# L3INIT_PRM register map
Vendor: Texas Instruments
Peripheral module from a debugger description file (folder TDA2Px).
Registers are 32-bit, access per field, reset 0x0 unless marked. A register's access mark holds for its fields unless they carry their own. Offsets are as the file gives them; lines under a group give offsets from that group; [hi:lo] are bit positions; {n}, {i} and the like mark numbered series; 'fields as' and 'values as' point back to an identical list; <NAME> marks a mode.

## L3INIT_PRM
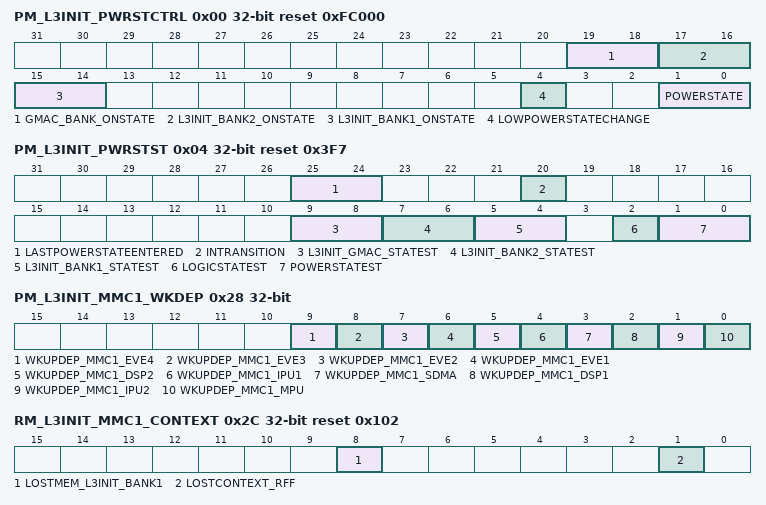
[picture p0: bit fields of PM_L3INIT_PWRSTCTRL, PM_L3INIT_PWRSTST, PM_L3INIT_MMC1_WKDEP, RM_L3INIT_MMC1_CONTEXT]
0x00 PM_L3INIT_PWRSTCTRL reset 0xFC000 — This register controls the L3INIT power state to reach upon a domain sleep transition Note: In the L3INIT power domain OFF state is only allowed in systems where Ethernet RGMII is NOT used in the system - this is very application specific and may not be available in all TI standard software offerings.
  [19:18] GMAC_BANK_ONSTATE ro — GMAC BANK state when domain is ON.
    3=MEM_ON (Memory bank is on when the domain is ON.)
  [17:16] L3INIT_BANK2_ONSTATE ro — L3INIT BANK2 state when domain is ON.
    3=MEM_ON (Memory bank is on when the domain is ON.)
  [15:14] L3INIT_BANK1_ONSTATE ro — L3INIT BANK1 state when domain is ON.
    3=MEM_ON (Memory bank is on when the domain is ON.)
  [4] LOWPOWERSTATECHANGE rw — Power state change request when domain has already performed a sleep transition. Allows going into deeper low power state without waking up the power domain.
    0=DIS (Do not request a low power state change.); 1=EN (Request a low power state change. This bit is automatically cleared when the power state is effectively changed or when power state is ON.)
  [1:0] POWERSTATE rw — Power state control
    0=OFF (OFF state); 1=RET (Reserved); 2=INACT (Reserved); 3=ON (ON State)
0x04 PM_L3INIT_PWRSTST reset 0x3F7 — This register provides a status on the current L3INIT power domain state. [warm reset insensitive]
  [25:24] LASTPOWERSTATEENTERED rw — Last low power state entered. Set to 0x3 upon write of the same only. This register is intended for debug purpose only.
    0=OFF (Power domain was previously OFF); 1=RET (Reserved); 2=INACTIVE (Reserved); 3=ON (Power domain was previously ON-ACTIVE)
  [20] INTRANSITION ro — Domain transition status
    0=NO (No on-going transition on power domain); 1=ONGOING (Power domain transition is in progress.)
  [9:8] L3INIT_GMAC_STATEST ro — L3INIT GMAC state status
    0=MEM_OFF (Memory is OFF); 3=MEM_ON (Memory is ON)
  [7:6] L3INIT_BANK2_STATEST ro — L3INIT BANK2 state status
    0=MEM_OFF (Memory is OFF); 1=MEM_RET (Reserved); 3=MEM_ON (Memory is ON)
  [5:4] L3INIT_BANK1_STATEST ro — L3INIT BANK1 state status
    0=MEM_OFF (Memory is OFF); 3=MEM_ON (Memory is ON)
  [2] LOGICSTATEST ro — Logic state status
    0=OFF (Reserved); 1=ON (Logic in domain is ON)
  [1:0] POWERSTATEST ro — Current power state status
    0=OFF (Power domain is OFF); 1=RET (Reserved); 2=INACTIVE (Reserved); 3=ON (Power domain is ON-ACTIVE)
0x10 RM_PCIESS_RSTCTRL reset 0x1 — This register controls the release of the PCIESS local reset.
  [0] RST_LOCAL_PCIE1 rw — PCIESS1 local reset control
    0=CLEAR (Reset is cleared for the IVA Sequencer CPU1); 1=ASSERT (Reset is asserted for the IVA sequencer CPU1)
0x14 RM_PCIESS_RSTST — This register logs the different reset sources of the PCIESS domain. Each bit is set upon release of the domain reset signal. Must be cleared by software. [warm reset insensitive]
  [0] RST_LOCAL_PCIE1 rw — PCIESS1 local SW reset
    0=RESET_NO (No SW reset occurred); 1=RESET_YES (Sequencer1 has been reset upon SW reset)
0x28 PM_L3INIT_MMC1_WKDEP — This register controls wakeup dependency based on MMC1 service requests.
  [all] fields
    0=DISABLED (Dependency is disabled); 1=ENABLED (Dependency is enabled)
  [9] WKUPDEP_MMC1_EVE4 rw — Wakeup dependency from MMC1 module (SWakeup signal) towards EVE4 + L3_MAIN1 + L4PER1 + L4PER2 + L4PER3 domainsEVE4 is not supported in this family of devices.
  [8] WKUPDEP_MMC1_EVE3 rw — Wakeup dependency from MMC1 module (SWakeup signal) towards EVE3 + L3_MAIN1 + L4PER1 + L4PER2 + L4PER3 domainsEVE3 is not supported in this family of devices.
  [7] WKUPDEP_MMC1_EVE2 rw — Wakeup dependency from MMC1 module (SWakeup signal) towards EVE2 + L3_MAIN1 + L4PER1 + L4PER2 + L4PER3 domains
  [6] WKUPDEP_MMC1_EVE1 rw — Wakeup dependency from MMC1 module (SWakeup signal) towards EVE1 + L3_MAIN1 + L4PER1 + L4PER2 + L4PER3 domains
  [5] WKUPDEP_MMC1_DSP2 rw — Wakeup dependency from MMC1 module (SWakeup signal) towards DSP2 + L3_MAIN1 + L4PER1 + L4PER2 + L4PER3 domains
  [4] WKUPDEP_MMC1_IPU1 rw — Wakeup dependency from MMC1 module (SWakeup signal) towards IPU1 + L3_MAIN1 + L4PER1 + L4PER2 + L4PER3 domains
  [3] WKUPDEP_MMC1_SDMA rw — Wakeup dependency from MMC1 module (SWakeup signal) towards SDMA + L3MAIN1 + L4PER1 + L4PER2 + L4PER3 domains
  [2] WKUPDEP_MMC1_DSP1 rw — Wakeup dependency from MMC1 module (SWakeup signal) towards DSP1 + L3_MAIN1 + L4PER1 + L4PER2 + L4PER3 domains
  [1] WKUPDEP_MMC1_IPU2 rw — Wakeup dependency from MMC1 module (SWakeup signal) towards IPU2 + L3_MAIN1 + L4PER1 + L4PER2 + L4PER3 domains
  [0] WKUPDEP_MMC1_MPU rw — Wakeup dependency from MMC1 module (SWakeup signal) towards MPU + L3_MAIN1 + L4PER1 + L4PER2 + L4PER3 domains
0x2C RM_L3INIT_MMC1_CONTEXT reset 0x102 — This register contains dedicated MMC1 context statuses. [warm reset insensitive]
  [8] LOSTMEM_L3INIT_BANK1 rw — Specify if memory-based context in L3INIT_BANK1 memory bank has been lost due to a previous power transition or other reset source.
    0=MAINTAINED (Context has been maintained); 1=LOST (Context has been lost)
  [1] LOSTCONTEXT_RFF rw — Specify if RFF-based context has been lost due to a previous power transition or other reset source. (set upon assertion of L3INIT_RET_RST signal)
    values as LOSTMEM_L3INIT_BANK1
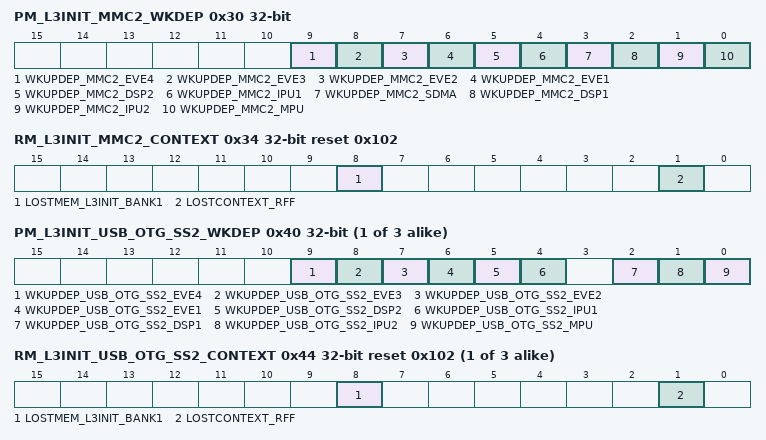
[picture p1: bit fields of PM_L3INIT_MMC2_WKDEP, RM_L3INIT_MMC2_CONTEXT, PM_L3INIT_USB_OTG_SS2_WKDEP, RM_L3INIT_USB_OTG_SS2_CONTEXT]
0x30 PM_L3INIT_MMC2_WKDEP — This register controls wakeup dependency based on MMC2 service requests.
  [all] fields
    values as the fields of PM_L3INIT_MMC1_WKDEP
  [9] WKUPDEP_MMC2_EVE4 rw — Wakeup dependency from MMC2 module (SWakeup signal) towards EVE4 + L3_MAIN1 + L4PER1 + L4PER2 + L4PER3 domainsEVE4 is not supported in this family of devices.
  [8] WKUPDEP_MMC2_EVE3 rw — Wakeup dependency from MMC2 module (SWakeup signal) towards EVE3 + L3_MAIN1 + L4PER1 + L4PER2 + L4PER3 domainsEVE3 is not supported in this family of devices.
  [7] WKUPDEP_MMC2_EVE2 rw — Wakeup dependency from MMC2 module (SWakeup signal) towards EVE2 + L3_MAIN1 + L4PER1 + L4PER2 + L4PER3 domains
  [6] WKUPDEP_MMC2_EVE1 rw — Wakeup dependency from MMC2 module (SWakeup signal) towards EVE1 + L3_MAIN1 + L4PER1 + L4PER2 + L4PER3 domains
  [5] WKUPDEP_MMC2_DSP2 rw — Wakeup dependency from MMC2 module (SWakeup signal) towards DSP2 + L3_MAIN1 + L4PER1 + L4PER2 + L4PER3 domains
  [4] WKUPDEP_MMC2_IPU1 rw — Wakeup dependency from MMC2 module (SWakeup signal) towards IPU1 + L3_MAIN1 + L4PER1 + L4PER2 + L4PER3 domains
  [3] WKUPDEP_MMC2_SDMA rw — Wakeup dependency from MMC2 module (SWakeup signal) towards SDMA + L3MAIN1 + L4PER1 + L4PER2 + L4PER3 domains
  [2] WKUPDEP_MMC2_DSP1 rw — Wakeup dependency from MMC2 module (SWakeup signal) towards DSP1 + L3_MAIN1 + L4PER1 + L4PER2 + L4PER3 domains
  [1] WKUPDEP_MMC2_IPU2 rw — Wakeup dependency from MMC2 module (SWakeup signal) towards IPU2 + L3_MAIN1 + L4PER1 + L4PER2 + L4PER3 domains
  [0] WKUPDEP_MMC2_MPU rw — Wakeup dependency from MMC2 module (SWakeup signal) towards MPU + L3_MAIN1 + L4PER1 + L4PER2 + L4PER3 domains
0x34 RM_L3INIT_MMC2_CONTEXT reset 0x102 — This register contains dedicated MMC2 context statuses. [warm reset insensitive]
  fields as RM_L3INIT_MMC1_CONTEXT
{0x30+8i} PM_L3INIT_USB_OTG_SS{i}_WKDEP (i=2..4) — This register controls wakeup dependency based on USB_OTG_SS{i} service requests.
  [all] fields
    values as the fields of PM_L3INIT_MMC1_WKDEP
  [9] WKUPDEP_USB_OTG_SS{i}_EVE4 rw — Wakeup dependency from USB{i} module (SWakeup signal) towards EVE4 + L3_MAIN1 + L4PER1 + L4PER2 + L4PER3 domainsEVE4 is not supported in this family of devices.
  [8] WKUPDEP_USB_OTG_SS{i}_EVE3 rw — Wakeup dependency from USB{i} module (SWakeup signal) towards EVE3 + L3_MAIN1 + L4PER1 + L4PER2 + L4PER3 domainsEVE3 is not supported in this family of devices.
  [7] WKUPDEP_USB_OTG_SS{i}_EVE2 rw — Wakeup dependency from USB{i} module (SWakeup signal) towards EVE2 + L3_MAIN1 + L4PER1 + L4PER2 + L4PER3 domains
  [6] WKUPDEP_USB_OTG_SS{i}_EVE1 rw — Wakeup dependency from USB{i} module (SWakeup signal) towards EVE1 + L3_MAIN1 + L4PER1 + L4PER2 + L4PER3 domains
  [5] WKUPDEP_USB_OTG_SS{i}_DSP2 rw — Wakeup dependency from USB{i} module (SWakeup signal) towards DSP2 + L3_MAIN1 + L4PER1 + L4PER2 + L4PER3 domains
  [4] WKUPDEP_USB_OTG_SS{i}_IPU1 rw — Wakeup dependency from USB{i} module (SWakeup signal) towards IPU1 + L3_MAIN1 + L4PER1 + L4PER2 + L4PER3 domains
  [2] WKUPDEP_USB_OTG_SS{i}_DSP1 rw — Wakeup dependency from USB{i} module (SWakeup signal) towards DSP1 + L3_MAIN1 + L4PER1 + L4PER2 + L4PER3 domains
  [1] WKUPDEP_USB_OTG_SS{i}_IPU2 rw — Wakeup dependency from USB{i} module (SWakeup signal) towards IPU2 + L3_MAIN1 + L4PER1 + L4PER2 + L4PER3 domains
  [0] WKUPDEP_USB_OTG_SS{i}_MPU rw — Wakeup dependency from USB{i} module (SWakeup signal) towards MPU + L3_MAIN1 + L4PER1 + L4PER2 + L4PER3 domains
{0x34+8i} RM_L3INIT_USB_OTG_SS{i}_CONTEXT reset 0x102 (i=2..4) — This register contains dedicated USB_OTG_SS{i} context statuses. [warm reset insensitive]
  fields as RM_L3INIT_MMC1_CONTEXT
0x7C RM_L3INIT_IEEE1500_2_OCP_CONTEXT reset 0x1 — This register contains dedicated IEEE1500_2_OCP context statuses. [warm reset insensitive]
  [0] LOSTCONTEXT_DFF rw — Specify if DFF-based context has been lost due to a previous power transition or other reset source. (set upon assertion of L3INIT_RST signal)
    values as RM_L3INIT_MMC1_CONTEXT.LOSTMEM_L3INIT_BANK1
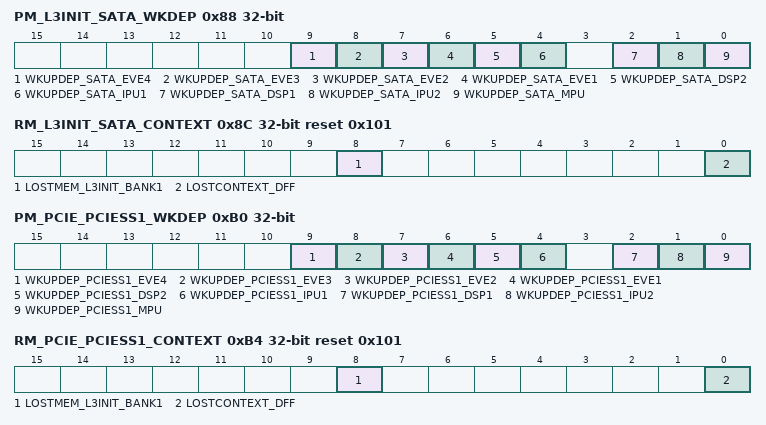
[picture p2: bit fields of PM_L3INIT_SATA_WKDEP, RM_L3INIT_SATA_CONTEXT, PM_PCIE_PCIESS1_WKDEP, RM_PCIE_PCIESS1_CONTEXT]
0x88 PM_L3INIT_SATA_WKDEP — This register controls wakeup dependency based on SATA service requests.
  [all] fields
    values as the fields of PM_L3INIT_MMC1_WKDEP
  [9] WKUPDEP_SATA_EVE4 rw — Wakeup dependency from SATA module (SWakeup signal) towards EVE4 + L3_MAIN1 + L4PER1 + L4PER2 + L4PER3 domainsEVE4 is not supported in this family of devices.
  [8] WKUPDEP_SATA_EVE3 rw — Wakeup dependency from SATA module (SWakeup signal) towards EVE3 + L3_MAIN1 + L4PER1 + L4PER2 + L4PER3 domainsEVE3 is not supported in this family of devices.
  [7] WKUPDEP_SATA_EVE2 rw — Wakeup dependency from SATA module (SWakeup signal) towards EVE2 + L3_MAIN1 + L4PER1 + L4PER2 + L4PER3 domains
  [6] WKUPDEP_SATA_EVE1 rw — Wakeup dependency from SATA module (SWakeup signal) towards EVE1 + L3_MAIN1 + L4PER1 + L4PER2 + L4PER3 domains
  [5] WKUPDEP_SATA_DSP2 rw — Wakeup dependency from SATA module (SWakeup signal) towards DSP2 + L3_MAIN1 + L4PER1 + L4PER2 + L4PER3 domains
  [4] WKUPDEP_SATA_IPU1 rw — Wakeup dependency from SATA module (SWakeup signal) towards IPU1 + L3_MAIN1 + L4PER1 + L4PER2 + L4PER3 domains
  [2] WKUPDEP_SATA_DSP1 rw — Wakeup dependency from SATA module (SWakeup signal) towards DSP1 + L3_MAIN1 + L4PER1 + L4PER2 + L4PER3 domains
  [1] WKUPDEP_SATA_IPU2 rw — Wakeup dependency from SATA module (SWakeup signal) towards IPU2 + L3_MAIN1 + L4PER1 + L4PER2 + L4PER3 domains
  [0] WKUPDEP_SATA_MPU rw — Wakeup dependency from SATA module (SWakeup signal) towards MPU + L3MAIN1 + L4CFG domains
0x8C RM_L3INIT_SATA_CONTEXT reset 0x101 — This register contains dedicated SATA context statuses. [warm reset insensitive]
  [8] LOSTMEM_L3INIT_BANK1 rw — Specify if memory-based context in L3INIT_BANK1 memory bank has been lost due to a previous power transition or other reset source.
    values as RM_L3INIT_MMC1_CONTEXT.LOSTMEM_L3INIT_BANK1
  [0] LOSTCONTEXT_DFF rw — Specify if DFF-based context has been lost due to a previous power transition or other reset source. (set upon assertion of L3INIT_RST signal)
    values as RM_L3INIT_MMC1_CONTEXT.LOSTMEM_L3INIT_BANK1
0xB0 PM_PCIE_PCIESS1_WKDEP — This register controls wakeup dependency based on PCIESS1 service requests.
  [9] WKUPDEP_PCIESS1_EVE4 rw — Wakeup dependency from PCIESS1 module (SWakeup signal) towards EVE4 + L3_MAIN1 + L4PER1 + L4PER2 + L4PER3 domainsEVE4 is not supported in this family of devices.
    values as the fields of PM_L3INIT_MMC1_WKDEP
  [8] WKUPDEP_PCIESS1_EVE3 rw — Wakeup dependency from PCIESS1 module (SWakeup signal) towards EVE3 + L3_MAIN1 + L4PER1 + L4PER2 + L4PER3 domainsEVE3 is not supported in this family of devices.
    values as the fields of PM_L3INIT_MMC1_WKDEP
  [7] WKUPDEP_PCIESS1_EVE2 rw — Wakeup dependency from PCIESS1 module (SWakeup signal) towards EVE2 + L3_MAIN1 + L4PER1 + L4PER2 + L4PER3 domains
    values as the fields of PM_L3INIT_MMC1_WKDEP
  [6] WKUPDEP_PCIESS1_EVE1 rw — Wakeup dependency from PCIESS1 module (SWakeup signal) towards EVE1 + L3_MAIN1 + L4PER1 + L4PER2 + L4PER3 domains
    values as the fields of PM_L3INIT_MMC1_WKDEP
  [5] WKUPDEP_PCIESS1_DSP2 rw — Wakeup dependency from PCIESS1 module (SWakeup signal) towards DSP2 + L3_MAIN1 + L4PER1 + L4PER2 + L4PER3 domains
    values as the fields of PM_L3INIT_MMC1_WKDEP
  [4] WKUPDEP_PCIESS1_IPU1 rw — Wakeup dependency from PCIESS1 module (SWakeup signal) towards IPU1 + L3_MAIN1 + L4PER1 + L4PER2 + L4PER3 domains
    values as the fields of PM_L3INIT_MMC1_WKDEP
  [2] WKUPDEP_PCIESS1_DSP1 rw — Wakeup dependency from PCIESS1 module (SWakeup signal) towards DSP1 + L3_MAIN1 + L4PER1 + L4PER2 + L4PER3 domains
    values as the fields of PM_L3INIT_MMC1_WKDEP
  [1] WKUPDEP_PCIESS1_IPU2 rw — Wakeup dependency from PCIESS1 module (SWakeup signal) towards IPU2 + L3_MAIN1 + L4PER1 + L4PER2 + L4PER3 domains
    0=Dependency_is_disabled; 1=Dependency_is_enabled
  [0] WKUPDEP_PCIESS1_MPU rw — Wakeup dependency from PCIESS1 module (SWakeup signal) towards MPU + L3_MAIN1 + L4PER1 + L4PER2 + L4PER3 domains
    values as the fields of PM_L3INIT_MMC1_WKDEP
0xB4 RM_PCIE_PCIESS1_CONTEXT reset 0x101 — This register contains dedicated PCIESS1 context statuses. [warm reset insensitive]
  [8] LOSTMEM_L3INIT_BANK1 rw — Specify if memory-based context in PCIESS1_BANK memory bank has been lost due to a previous power transition or other reset source.
    values as RM_L3INIT_MMC1_CONTEXT.LOSTMEM_L3INIT_BANK1
  [0] LOSTCONTEXT_DFF rw — Specify if DFF-based context has been lost due to a previous power transition or other reset source. (set upon assertion of L3INIT_RST signal)
    values as RM_L3INIT_MMC1_CONTEXT.LOSTMEM_L3INIT_BANK1
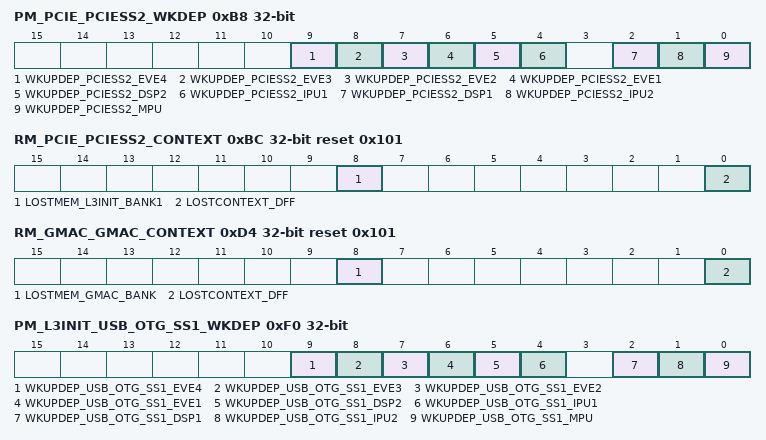
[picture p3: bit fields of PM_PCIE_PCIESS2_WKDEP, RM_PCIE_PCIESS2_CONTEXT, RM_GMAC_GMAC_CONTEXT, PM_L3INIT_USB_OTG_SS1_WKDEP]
0xB8 PM_PCIE_PCIESS2_WKDEP — This register controls wakeup dependency based on PCIESS2 service requests.
  [all] fields
    values as the fields of PM_L3INIT_MMC1_WKDEP
  [9] WKUPDEP_PCIESS2_EVE4 rw — Wakeup dependency from PCIESS2 module (SWakeup signal) towards EVE4 + L3_MAIN1 + L4PER1 + L4PER2 + L4PER3 domainsEVE4 is not supported in this family of devices.
  [8] WKUPDEP_PCIESS2_EVE3 rw — Wakeup dependency from PCIESS2 module (SWakeup signal) towards EVE3 + L3_MAIN1 + L4PER1 + L4PER2 + L4PER3 domainsEVE3 is not supported in this family of devices.
  [7] WKUPDEP_PCIESS2_EVE2 rw — Wakeup dependency from PCIESS2 module (SWakeup signal) towards EVE2 + L3_MAIN1 + L4PER1 + L4PER2 + L4PER3 domains
  [6] WKUPDEP_PCIESS2_EVE1 rw — Wakeup dependency from PCIESS2 module (SWakeup signal) towards EVE1 + L3_MAIN1 + L4PER1 + L4PER2 + L4PER3 domains
  [5] WKUPDEP_PCIESS2_DSP2 rw — Wakeup dependency from PCIESS2 module (SWakeup signal) towards DSP2 + L3_MAIN1 + L4PER1 + L4PER2 + L4PER3 domains
  [4] WKUPDEP_PCIESS2_IPU1 rw — Wakeup dependency from PCIESS2 module (SWakeup signal) towards IPU1 + L3_MAIN1 + L4PER1 + L4PER2 + L4PER3 domains
  [2] WKUPDEP_PCIESS2_DSP1 rw — Wakeup dependency from PCIESS2 module (SWakeup signal) towards DSP1 + L3_MAIN1 + L4PER1 + L4PER2 + L4PER3 domains
  [1] WKUPDEP_PCIESS2_IPU2 rw — Wakeup dependency from PCIESS2 module (SWakeup signal) towards IPU2 + L3_MAIN1 + L4PER1 + L4PER2 + L4PER3 domains
  [0] WKUPDEP_PCIESS2_MPU rw — Wakeup dependency from PCIESS2 module (SWakeup signal) towards MPU + L3_MAIN1 + L4PER1 + L4PER2 + L4PER3 domains
0xBC RM_PCIE_PCIESS2_CONTEXT reset 0x101 — This register contains dedicated PCIESS2 context statuses. [warm reset insensitive]
  fields as RM_PCIE_PCIESS1_CONTEXT
0xD4 RM_GMAC_GMAC_CONTEXT reset 0x101 — This register contains dedicated GMAC context statuses. [warm reset insensitive]
  [8] LOSTMEM_GMAC_BANK rw — Specify if memory-based context in GMAC_BANK memory bank has been lost due to a previous power transition or other reset source.
    values as RM_L3INIT_MMC1_CONTEXT.LOSTMEM_L3INIT_BANK1
  [0] LOSTCONTEXT_DFF rw — Specify if DFF-based context has been lost due to a previous power transition or other reset source. (set upon assertion of L3INIT_RST signal)
    values as RM_L3INIT_MMC1_CONTEXT.LOSTMEM_L3INIT_BANK1
0xE4 RM_L3INIT_OCP2SCP1_CONTEXT reset 0x1 — This register contains dedicated OCP2SCP1 context statuses. [warm reset insensitive]
  fields as RM_L3INIT_IEEE1500_2_OCP_CONTEXT
0xEC RM_L3INIT_OCP2SCP3_CONTEXT reset 0x1 — This register contains dedicated OCP2SCP3 context statuses. [warm reset insensitive]
  fields as RM_L3INIT_IEEE1500_2_OCP_CONTEXT
0xF0 PM_L3INIT_USB_OTG_SS1_WKDEP — This register controls wakeup dependency based on USB_OTG_SS1 service requests.
  [all] fields
    values as the fields of PM_L3INIT_MMC1_WKDEP
  [9] WKUPDEP_USB_OTG_SS1_EVE4 rw — Wakeup dependency from USB1 module (SWakeup signal) towards EVE4 + L3_MAIN1 + L4PER1 + L4PER2 + L4PER3 domainsEVE4 is not supported in this family of devices.
  [8] WKUPDEP_USB_OTG_SS1_EVE3 rw — Wakeup dependency from USB1 module (SWakeup signal) towards EVE3 + L3_MAIN1 + L4PER1 + L4PER2 + L4PER3 domainsEVE3 is not supported in this family of devices.
  [7] WKUPDEP_USB_OTG_SS1_EVE2 rw — Wakeup dependency from USB1 module (SWakeup signal) towards EVE2 + L3_MAIN1 + L4PER1 + L4PER2 + L4PER3 domains
  [6] WKUPDEP_USB_OTG_SS1_EVE1 rw — Wakeup dependency from USB1 module (SWakeup signal) towards EVE1 + L3_MAIN1 + L4PER1 + L4PER2 + L4PER3 domains
  [5] WKUPDEP_USB_OTG_SS1_DSP2 rw — Wakeup dependency from USB1 module (SWakeup signal) towards DSP2 + L3_MAIN1 + L4PER1 + L4PER2 + L4PER3 domains
  [4] WKUPDEP_USB_OTG_SS1_IPU1 rw — Wakeup dependency from USB1 module (SWakeup signal) towards IPU1 + L3_MAIN1 + L4PER1 + L4PER2 + L4PER3 domains
  [2] WKUPDEP_USB_OTG_SS1_DSP1 rw — Wakeup dependency from USB1 module (SWakeup signal) towards DSP1 + L3_MAIN1 + L4PER1 + L4PER2 + L4PER3 domains
  [1] WKUPDEP_USB_OTG_SS1_IPU2 rw — Wakeup dependency from USB1 module (SWakeup signal) towards IPU2 + L3_MAIN1 + L4PER1 + L4PER2 + L4PER3 domains
  [0] WKUPDEP_USB_OTG_SS1_MPU rw — Wakeup dependency from USB1 module (SWakeup signal) towards MPU + L3_MAIN1 + L4PER1 + L4PER2 + L4PER3 domains
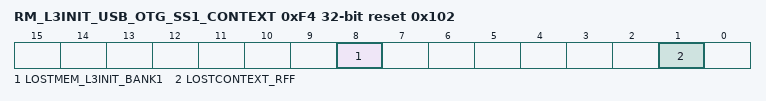
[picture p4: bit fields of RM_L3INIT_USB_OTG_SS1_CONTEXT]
0xF4 RM_L3INIT_USB_OTG_SS1_CONTEXT reset 0x102 — This register contains dedicated USB_OTG_SS1 context statuses. [warm reset insensitive]
  fields as RM_L3INIT_MMC1_CONTEXT
